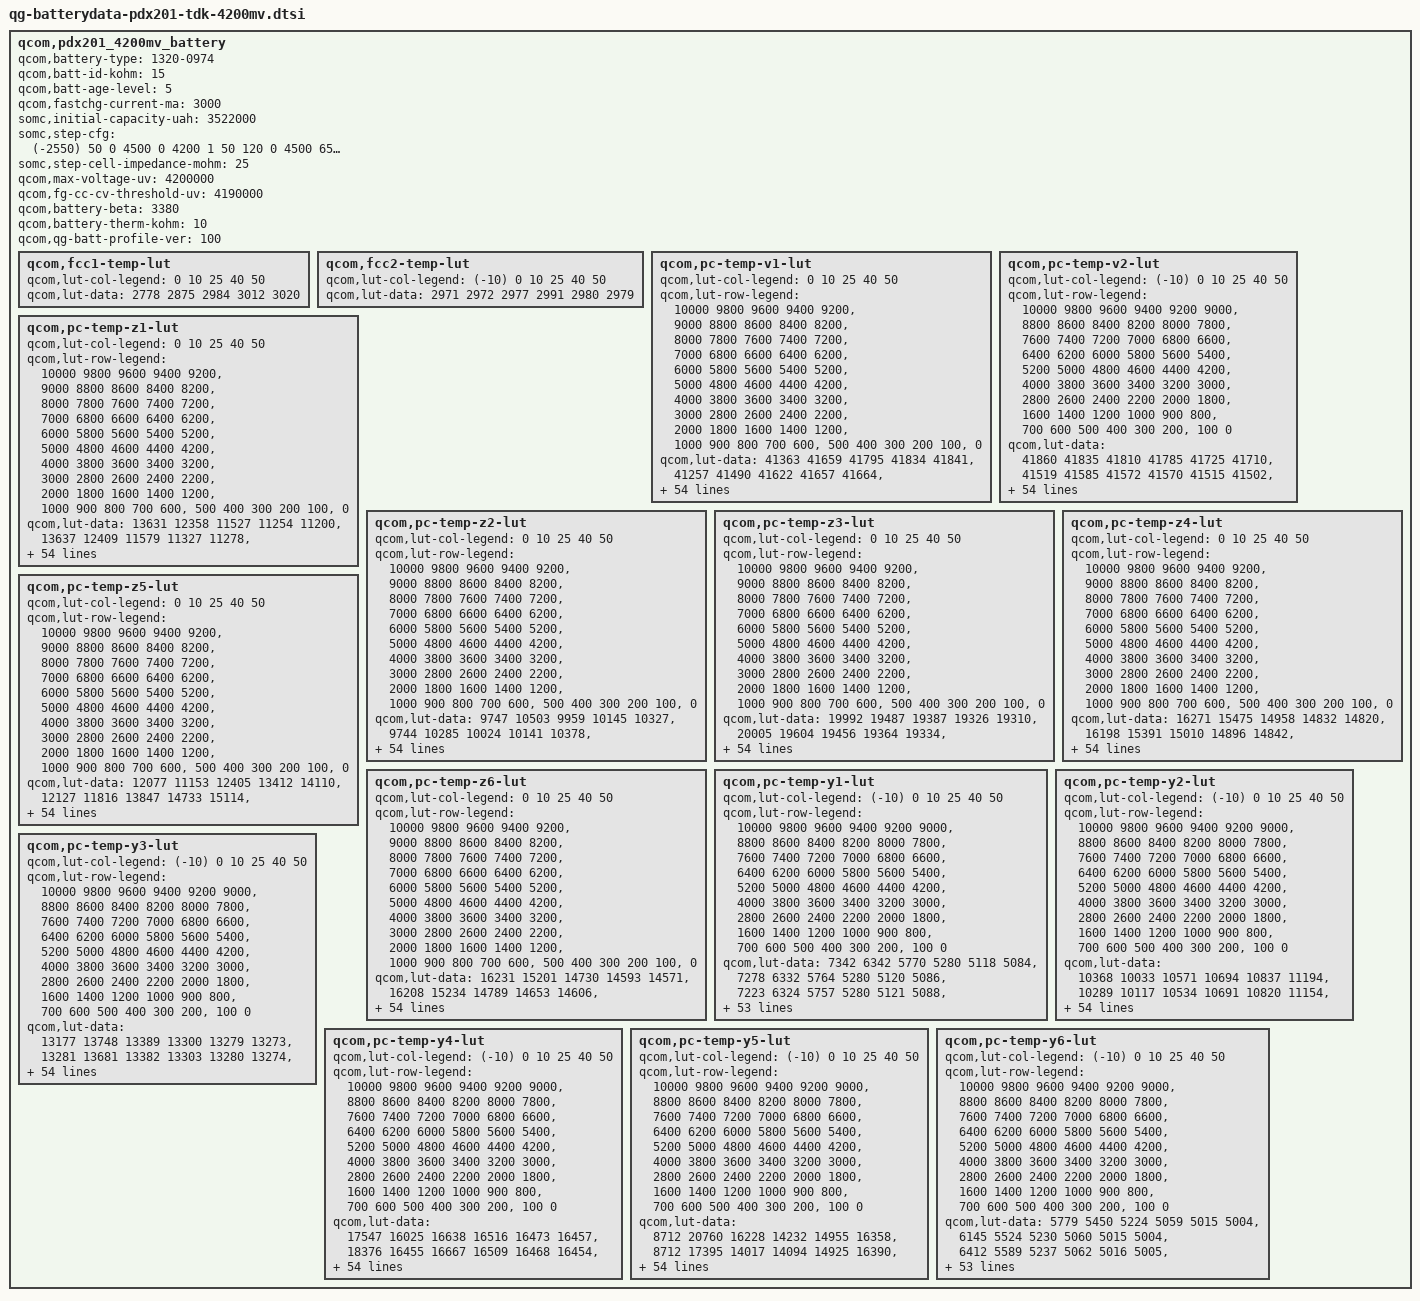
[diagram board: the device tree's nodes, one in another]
// SPDX-License-Identifier: GPL-2.0-only
/*
 * Copyright (c) 2019, The Linux Foundation. All rights reserved.
 */

qcom,pdx201_4200mv_battery {
	/* Added or Modified by SOMC */
	qcom,battery-type = "1320-0974";
	qcom,batt-id-kohm = <15>;
	qcom,batt-age-level = <5>;
	qcom,fastchg-current-ma = <3000>;
	somc,initial-capacity-uah = <3522000>;
	somc,step-cfg = <
		(-2550) 50    0 4500    0 4200 1
		   50  120    0 4500  650 4200 2
		  120  200    0 4100 1700 4200 3
		  120  200 4100 4500 1200 4200 3
		  200  450    0 4150 2400 4200 3
		  200  450 4150 4500 1700 4200 3
		  450  550    0 4500 1000 4200 4
		  550 2550    0 4500    0 4200 5
	>;
	somc,step-cell-impedance-mohm = <25>;

	/* Prepared by Qualcomm */
	/* 4176720_SoMC_Amuro2_2958mAh_averaged_MasterSlave_Sept16th2019 */
	qcom,max-voltage-uv = <4200000>;
	qcom,fg-cc-cv-threshold-uv = <4190000>;
	/* qcom,fastchg-current-ma = <1500>; */
	/* qcom,batt-id-kohm = <330>; */
	qcom,battery-beta = <3380>;
	qcom,battery-therm-kohm = <10>;
	/* qcom,battery-type = "4176720_SoMC_Amuro2_2958mAh_averaged_MasterSlave_Sept16th2019"; */
	qcom,qg-batt-profile-ver = <100>;

	qcom,fcc1-temp-lut {
		qcom,lut-col-legend = <0 10 25 40 50>;
		qcom,lut-data = <2778 2875 2984 3012 3020>;
	};

	qcom,fcc2-temp-lut {
		qcom,lut-col-legend = <(-10) 0 10 25 40 50>;
		qcom,lut-data = <2971 2972 2977 2991 2980 2979>;
	};

	qcom,pc-temp-v1-lut {
		qcom,lut-col-legend = <0 10 25 40 50>;
		qcom,lut-row-legend = <10000 9800 9600 9400 9200>,
			<9000 8800 8600 8400 8200>,
			<8000 7800 7600 7400 7200>,
			<7000 6800 6600 6400 6200>,
			<6000 5800 5600 5400 5200>,
			<5000 4800 4600 4400 4200>,
			<4000 3800 3600 3400 3200>,
			<3000 2800 2600 2400 2200>,
			<2000 1800 1600 1400 1200>,
			<1000 900 800 700 600>,
			<500 400 300 200 100>,
			<0>;
		qcom,lut-data = <41363 41659 41795 41834 41841>,
			<41257 41490 41622 41657 41664>,
			<41117 41335 41439 41473 41481>,
			<40935 41186 41267 41291 41298>,
			<40706 41032 41122 41115 41118>,
			<40473 40872 40979 40945 40941>,
			<40225 40695 40803 40775 40767>,
			<40003 40460 40584 40597 40595>,
			<39868 40171 40370 40420 40429>,
			<39778 39968 40165 40255 40270>,
			<39698 39863 39986 40098 40116>,
			<39618 39783 39868 39953 39968>,
			<39540 39694 39785 39821 39829>,
			<39454 39605 39693 39694 39694>,
			<39354 39509 39573 39570 39565>,
			<39251 39399 39438 39447 39441>,
			<39152 39278 39293 39300 39298>,
			<39056 39151 39136 39105 39112>,
			<38963 39014 38975 38922 38929>,
			<38874 38875 38786 38781 38789>,
			<38787 38731 38619 38660 38669>,
			<38699 38585 38528 38562 38567>,
			<38606 38481 38469 38481 38479>,
			<38520 38409 38413 38407 38398>,
			<38452 38354 38358 38335 38320>,
			<38394 38313 38306 38266 38246>,
			<38348 38281 38255 38205 38181>,
			<38312 38253 38207 38147 38122>,
			<38283 38225 38163 38096 38068>,
			<38258 38199 38123 38053 38021>,
			<38237 38173 38086 38015 37977>,
			<38218 38148 38056 37980 37938>,
			<38200 38124 38029 37948 37902>,
			<38182 38101 37999 37913 37863>,
			<38161 38078 37972 37877 37815>,
			<38127 38042 37936 37835 37761>,
			<38083 37989 37884 37781 37703>,
			<38025 37923 37812 37714 37639>,
			<37941 37847 37735 37637 37565>,
			<37841 37756 37650 37549 37478>,
			<37733 37651 37552 37448 37377>,
			<37612 37524 37429 37326 37255>,
			<37493 37397 37296 37193 37121>,
			<37381 37277 37175 37074 37003>,
			<37304 37207 37094 36993 36927>,
			<37258 37165 37052 36956 36890>,
			<37240 37151 37040 36943 36876>,
			<37216 37132 37025 36926 36859>,
			<37138 37075 36977 36871 36789>,
			<36915 36864 36774 36654 36551>,
			<36551 36506 36431 36311 36201>,
			<36108 36066 35997 35878 35764>,
			<35548 35511 35444 35327 35208>,
			<34814 34768 34704 34590 34461>,
			<33643 33611 33585 33479 33331>,
			<30000 30000 30000 30000 30000>;
	};

	qcom,pc-temp-v2-lut {
		qcom,lut-col-legend = <(-10) 0 10 25 40 50>;
		qcom,lut-row-legend = <10000 9800 9600 9400 9200 9000>,
			<8800 8600 8400 8200 8000 7800>,
			<7600 7400 7200 7000 6800 6600>,
			<6400 6200 6000 5800 5600 5400>,
			<5200 5000 4800 4600 4400 4200>,
			<4000 3800 3600 3400 3200 3000>,
			<2800 2600 2400 2200 2000 1800>,
			<1600 1400 1200 1000 900 800>,
			<700 600 500 400 300 200>,
			<100 0>;
		qcom,lut-data = <41860 41835 41810 41785 41725 41710>,
			<41519 41585 41572 41570 41515 41502>,
			<41273 41364 41357 41366 41315 41305>,
			<41172 41179 41171 41174 41124 41116>,
			<41134 41028 41014 40992 40943 40937>,
			<41075 40863 40853 40822 40771 40763>,
			<40784 40651 40681 40675 40611 40595>,
			<40344 40416 40497 40528 40457 40431>,
			<40042 40178 40276 40328 40287 40270>,
			<39806 39923 40003 40063 40102 40113>,
			<39624 39730 39797 39870 39937 39962>,
			<39503 39622 39691 39774 39809 39822>,
			<39398 39534 39605 39693 39691 39688>,
			<39258 39416 39485 39585 39567 39554>,
			<39084 39272 39334 39454 39439 39425>,
			<38877 39119 39175 39304 39295 39282>,
			<38567 38957 39006 39116 39110 39100>,
			<38268 38795 38841 38924 38917 38911>,
			<38163 38660 38706 38768 38760 38756>,
			<38116 38547 38592 38631 38621 38621>,
			<38076 38424 38488 38516 38506 38506>,
			<38036 38257 38394 38421 38412 38411>,
			<37999 38100 38308 38336 38329 38327>,
			<37962 38014 38231 38257 38250 38247>,
			<37924 37958 38162 38185 38177 38175>,
			<37888 37917 38092 38119 38111 38107>,
			<37855 37888 38015 38059 38051 38046>,
			<37824 37862 37944 38002 37996 37989>,
			<37791 37832 37891 37950 37945 37935>,
			<37757 37800 37850 37902 37897 37886>,
			<37723 37769 37813 37855 37849 37836>,
			<37692 37743 37781 37809 37801 37789>,
			<37659 37716 37749 37761 37748 37734>,
			<37620 37683 37715 37709 37679 37652>,
			<37575 37644 37678 37656 37595 37544>,
			<37526 37601 37637 37599 37517 37452>,
			<37473 37553 37588 37536 37449 37381>,
			<37414 37498 37532 37470 37383 37315>,
			<37346 37432 37465 37405 37318 37249>,
			<37270 37353 37387 37336 37252 37185>,
			<37198 37266 37301 37255 37174 37108>,
			<37132 37162 37204 37155 37077 37008>,
			<37069 37057 37094 37034 36966 36900>,
			<37007 36957 36967 36914 36849 36790>,
			<36933 36891 36906 36877 36821 36763>,
			<36862 36836 36874 36852 36794 36736>,
			<36807 36805 36854 36830 36771 36715>,
			<36735 36761 36824 36799 36734 36677>,
			<36635 36671 36749 36703 36631 36559>,
			<36439 36490 36547 36447 36370 36274>,
			<36127 36161 36179 36064 35986 35882>,
			<35695 35700 35709 35585 35505 35399>,
			<35117 35109 35124 34984 34898 34778>,
			<34298 34325 34351 34169 34071 33930>,
			<33099 33187 33260 32937 32865 32691>,
			<29585 29616 29564 29645 29742 29541>;
	};

	qcom,pc-temp-z1-lut {
		qcom,lut-col-legend = <0 10 25 40 50>;
		qcom,lut-row-legend = <10000 9800 9600 9400 9200>,
			<9000 8800 8600 8400 8200>,
			<8000 7800 7600 7400 7200>,
			<7000 6800 6600 6400 6200>,
			<6000 5800 5600 5400 5200>,
			<5000 4800 4600 4400 4200>,
			<4000 3800 3600 3400 3200>,
			<3000 2800 2600 2400 2200>,
			<2000 1800 1600 1400 1200>,
			<1000 900 800 700 600>,
			<500 400 300 200 100>,
			<0>;
		qcom,lut-data = <13631 12358 11527 11254 11200>,
			<13637 12409 11579 11327 11278>,
			<13645 12445 11618 11357 11303>,
			<13655 12473 11646 11377 11323>,
			<13669 12480 11660 11390 11336>,
			<13676 12475 11668 11399 11345>,
			<13678 12467 11667 11403 11350>,
			<13678 12461 11662 11402 11354>,
			<13677 12455 11658 11401 11356>,
			<13669 12453 11658 11402 11358>,
			<13664 12456 11659 11405 11359>,
			<13670 12463 11662 11409 11360>,
			<13678 12470 11672 11411 11361>,
			<13683 12479 11680 11413 11363>,
			<13694 12487 11683 11415 11363>,
			<13707 12494 11686 11416 11364>,
			<13710 12502 11689 11417 11364>,
			<13710 12508 11693 11418 11365>,
			<13708 12512 11696 11419 11365>,
			<13705 12516 11699 11420 11366>,
			<13699 12521 11701 11422 11369>,
			<13696 12526 11704 11424 11370>,
			<13694 12530 11708 11427 11371>,
			<13693 12535 11712 11429 11372>,
			<13692 12540 11716 11432 11375>,
			<13690 12544 11719 11434 11378>,
			<13688 12551 11722 11437 11380>,
			<13689 12555 11725 11439 11381>,
			<13690 12552 11728 11442 11382>,
			<13691 12549 11732 11443 11384>,
			<13693 12549 11736 11445 11385>,
			<13696 12554 11738 11446 11386>,
			<13699 12559 11741 11447 11387>,
			<13702 12563 11744 11448 11388>,
			<13705 12568 11749 11449 11388>,
			<13711 12574 11753 11450 11389>,
			<13720 12583 11754 11451 11389>,
			<13721 12590 11754 11452 11390>,
			<13704 12590 11755 11453 11391>,
			<13683 12588 11758 11454 11392>,
			<13671 12589 11761 11455 11392>,
			<13664 12599 11761 11455 11393>,
			<13655 12603 11762 11455 11393>,
			<13645 12596 11764 11456 11393>,
			<13621 12588 11770 11457 11394>,
			<13621 12608 11769 11458 11394>,
			<13617 12584 11771 11457 11395>,
			<13639 12590 11770 11458 11394>,
			<13640 12590 11772 11459 11394>,
			<13624 12603 11778 11460 11395>,
			<13638 12609 11787 11464 11397>,
			<13669 12634 11797 11471 11403>,
			<13728 12685 11818 11479 11410>,
			<13708 12704 11843 11494 11421>,
			<13708 12704 11843 11494 11421>,
			<13708 12704 11843 11494 11421>;
	};

	qcom,pc-temp-z2-lut {
		qcom,lut-col-legend = <0 10 25 40 50>;
		qcom,lut-row-legend = <10000 9800 9600 9400 9200>,
			<9000 8800 8600 8400 8200>,
			<8000 7800 7600 7400 7200>,
			<7000 6800 6600 6400 6200>,
			<6000 5800 5600 5400 5200>,
			<5000 4800 4600 4400 4200>,
			<4000 3800 3600 3400 3200>,
			<3000 2800 2600 2400 2200>,
			<2000 1800 1600 1400 1200>,
			<1000 900 800 700 600>,
			<500 400 300 200 100>,
			<0>;
		qcom,lut-data = <9747 10503 9959 10145 10327>,
			<9744 10285 10024 10141 10378>,
			<9740 10161 10225 10449 10729>,
			<9732 10069 10320 10778 11102>,
			<9720 10028 10290 10791 11124>,
			<9715 10028 10249 10776 11027>,
			<9719 10030 10234 10753 10979>,
			<9725 9981 10232 10703 10990>,
			<9732 9866 10222 10633 11001>,
			<9741 9810 10145 10478 10873>,
			<9748 9822 10068 10232 10497>,
			<9754 9844 10057 10163 10349>,
			<9758 9863 10049 10195 10364>,
			<9762 9880 10047 10228 10385>,
			<9765 9900 10081 10228 10393>,
			<9769 9925 10132 10219 10395>,
			<9774 9951 10158 10231 10405>,
			<9781 9970 10177 10371 10439>,
			<9789 9984 10182 10489 10470>,
			<9795 9996 10167 10405 10467>,
			<9801 10013 10150 10236 10442>,
			<9807 10031 10147 10199 10437>,
			<9817 10036 10150 10241 10472>,
			<9825 10022 10156 10294 10502>,
			<9828 10005 10179 10362 10462>,
			<9829 9999 10206 10433 10376>,
			<9830 9996 10219 10433 10324>,
			<9828 9996 10230 10371 10288>,
			<9825 9998 10233 10334 10271>,
			<9825 10003 10216 10338 10279>,
			<9826 10008 10199 10345 10298>,
			<9828 10017 10200 10357 10322>,
			<9829 10023 10206 10375 10361>,
			<9831 10025 10215 10396 10404>,
			<9833 10027 10236 10426 10459>,
			<9835 10030 10257 10454 10510>,
			<9838 10035 10267 10469 10534>,
			<9842 10042 10276 10483 10550>,
			<9853 10048 10280 10498 10564>,
			<9869 10055 10285 10518 10582>,
			<9885 10059 10292 10532 10594>,
			<9903 10061 10300 10520 10589>,
			<9927 10066 10307 10498 10580>,
			<9965 10090 10302 10493 10574>,
			<10203 10207 10347 10498 10594>,
			<10210 10266 10390 10528 10626>,
			<10206 10256 10365 10525 10624>,
			<10206 10252 10333 10527 10681>,
			<10232 10283 10380 10643 10777>,
			<10252 10309 10465 10626 10537>,
			<10212 10262 10419 10527 10444>,
			<10108 10237 10374 10467 10371>,
			<10017 10179 10315 10386 10322>,
			<9654 10025 10258 10319 10251>,
			<9654 10025 10258 10319 10251>,
			<9654 10025 10258 10319 10251>;
	};

	qcom,pc-temp-z3-lut {
		qcom,lut-col-legend = <0 10 25 40 50>;
		qcom,lut-row-legend = <10000 9800 9600 9400 9200>,
			<9000 8800 8600 8400 8200>,
			<8000 7800 7600 7400 7200>,
			<7000 6800 6600 6400 6200>,
			<6000 5800 5600 5400 5200>,
			<5000 4800 4600 4400 4200>,
			<4000 3800 3600 3400 3200>,
			<3000 2800 2600 2400 2200>,
			<2000 1800 1600 1400 1200>,
			<1000 900 800 700 600>,
			<500 400 300 200 100>,
			<0>;
		qcom,lut-data = <19992 19487 19387 19326 19310>,
			<20005 19604 19456 19364 19334>,
			<20018 19695 19493 19381 19353>,
			<20040 19771 19511 19392 19363>,
			<20081 19802 19517 19406 19369>,
			<20112 19806 19521 19420 19374>,
			<20134 19802 19524 19425 19375>,
			<20148 19792 19525 19416 19373>,
			<20142 19778 19524 19403 19369>,
			<20101 19759 19508 19390 19361>,
			<20061 19726 19484 19374 19343>,
			<20037 19692 19459 19367 19335>,
			<20018 19677 19427 19365 19331>,
			<20012 19668 19413 19365 19327>,
			<20012 19664 19429 19365 19326>,
			<20013 19666 19456 19364 19327>,
			<20016 19670 19479 19367 19330>,
			<20021 19678 19502 19385 19341>,
			<20025 19702 19512 19400 19351>,
			<20027 19728 19514 19390 19344>,
			<20030 19748 19514 19371 19325>,
			<20034 19767 19507 19363 19320>,
			<20049 19772 19491 19358 19328>,
			<20063 19755 19479 19356 19338>,
			<20064 19733 19471 19371 19353>,
			<20058 19719 19466 19396 19372>,
			<20050 19708 19474 19408 19376>,
			<20041 19700 19495 19415 19373>,
			<20030 19694 19507 19419 19369>,
			<20019 19690 19513 19415 19366>,
			<20009 19690 19516 19407 19362>,
			<19999 19691 19513 19401 19358>,
			<19988 19692 19504 19395 19352>,
			<19977 19690 19498 19391 19350>,
			<19968 19688 19493 19387 19351>,
			<19963 19687 19491 19384 19353>,
			<19959 19687 19490 19381 19352>,
			<19952 19686 19490 19378 19350>,
			<19936 19682 19489 19376 19348>,
			<19917 19670 19483 19376 19345>,
			<19902 19662 19477 19376 19342>,
			<19888 19659 19474 19375 19342>,
			<19862 19653 19472 19372 19342>,
			<19811 19637 19465 19370 19343>,
			<19669 19563 19444 19364 19338>,
			<19645 19535 19423 19343 19327>,
			<19634 19528 19413 19341 19325>,
			<19619 19521 19408 19339 19319>,
			<19613 19514 19402 19329 19317>,
			<19606 19508 19391 19334 19338>,
			<19602 19515 19396 19339 19346>,
			<19598 19507 19390 19345 19346>,
			<19564 19472 19391 19349 19345>,
			<19422 19411 19381 19357 19356>,
			<19422 19411 19381 19357 19356>,
			<19422 19411 19381 19357 19356>;
	};

	qcom,pc-temp-z4-lut {
		qcom,lut-col-legend = <0 10 25 40 50>;
		qcom,lut-row-legend = <10000 9800 9600 9400 9200>,
			<9000 8800 8600 8400 8200>,
			<8000 7800 7600 7400 7200>,
			<7000 6800 6600 6400 6200>,
			<6000 5800 5600 5400 5200>,
			<5000 4800 4600 4400 4200>,
			<4000 3800 3600 3400 3200>,
			<3000 2800 2600 2400 2200>,
			<2000 1800 1600 1400 1200>,
			<1000 900 800 700 600>,
			<500 400 300 200 100>,
			<0>;
		qcom,lut-data = <16271 15475 14958 14832 14820>,
			<16198 15391 15010 14896 14842>,
			<16107 15298 14957 14874 14831>,
			<15989 15197 14909 14834 14795>,
			<15850 15111 14881 14806 14770>,
			<15733 15023 14857 14783 14750>,
			<15637 14965 14829 14762 14731>,
			<15554 14968 14798 14741 14713>,
			<15484 14986 14782 14726 14700>,
			<15424 14995 14782 14724 14698>,
			<15371 14977 14787 14729 14707>,
			<15320 14947 14790 14724 14707>,
			<15273 14921 14794 14713 14700>,
			<15236 14894 14794 14703 14693>,
			<15208 14875 14769 14696 14687>,
			<15185 14868 14738 14690 14680>,
			<15166 14863 14737 14693 14680>,
			<15150 14863 14748 14735 14722>,
			<15138 14868 14764 14787 14778>,
			<15129 14878 14836 14833 14819>,
			<15121 14908 14911 14874 14856>,
			<15119 14959 14917 14882 14863>,
			<15124 14980 14913 14876 14845>,
			<15131 14984 14907 14866 14820>,
			<15136 14985 14900 14837 14791>,
			<15140 14983 14890 14795 14755>,
			<15142 14975 14869 14766 14734>,
			<15140 14966 14833 14744 14722>,
			<15133 14956 14807 14729 14712>,
			<15125 14944 14787 14719 14702>,
			<15114 14932 14775 14712 14694>,
			<15101 14920 14772 14710 14691>,
			<15089 14910 14771 14709 14690>,
			<15077 14903 14771 14709 14690>,
			<15066 14898 14772 14715 14701>,
			<15056 14899 14775 14725 14716>,
			<15047 14909 14786 14738 14723>,
			<15040 14919 14807 14754 14728>,
			<15035 14923 14813 14759 14729>,
			<15029 14925 14811 14754 14727>,
			<15021 14926 14810 14748 14725>,
			<15010 14921 14813 14754 14728>,
			<14991 14912 14816 14763 14735>,
			<14952 14881 14806 14760 14733>,
			<14849 14808 14766 14740 14720>,
			<14831 14774 14724 14705 14681>,
			<14829 14772 14720 14689 14662>,
			<14824 14766 14713 14676 14654>,
			<14818 14764 14719 14693 14672>,
			<14827 14782 14754 14715 14668>,
			<14854 14785 14753 14714 14663>,
			<14874 14793 14760 14707 14663>,
			<14913 14827 14757 14701 14663>,
			<15071 14884 14763 14690 14652>,
			<15071 14884 14763 14690 14652>,
			<15071 14884 14763 14690 14652>;
	};

	qcom,pc-temp-z5-lut {
		qcom,lut-col-legend = <0 10 25 40 50>;
		qcom,lut-row-legend = <10000 9800 9600 9400 9200>,
			<9000 8800 8600 8400 8200>,
			<8000 7800 7600 7400 7200>,
			<7000 6800 6600 6400 6200>,
			<6000 5800 5600 5400 5200>,
			<5000 4800 4600 4400 4200>,
			<4000 3800 3600 3400 3200>,
			<3000 2800 2600 2400 2200>,
			<2000 1800 1600 1400 1200>,
			<1000 900 800 700 600>,
			<500 400 300 200 100>,
			<0>;
		qcom,lut-data = <12077 11153 12405 13412 14110>,
			<12127 11816 13847 14733 15114>,
			<12206 12470 14746 15327 15991>,
			<12365 13130 15343 15775 16527>,
			<12685 13849 15686 16659 17195>,
			<13055 14786 16036 18032 17986>,
			<13566 15506 16749 19075 18936>,
			<14002 15728 17857 19684 20495>,
			<14094 15871 18318 19868 21803>,
			<14110 15918 17716 18982 20944>,
			<14131 15636 16826 17193 18036>,
			<14222 15272 16008 16903 16968>,
			<14429 15314 14769 17499 17057>,
			<14724 15897 14230 18253 17221>,
			<15316 16682 15491 18940 17671>,
			<16080 17494 18034 19760 18760>,
			<16781 18571 22683 21584 20311>,
			<17469 20371 30354 28521 23670>,
			<18173 24019 33594 34051 26544>,
			<18902 27683 32166 30052 24169>,
			<19718 30714 29823 21354 17825>,
			<20762 33773 27121 17425 15298>,
			<22615 34532 22497 15722 14843>,
			<24204 30492 19379 15008 14677>,
			<24440 25519 17675 15574 15551>,
			<24436 23377 16719 16765 17355>,
			<24386 21998 17133 18087 18446>,
			<24009 21272 18528 20026 19032>,
			<23288 20897 19964 21799 19724>,
			<22728 20674 21972 23150 21085>,
			<22318 20767 23554 24229 22654>,
			<21987 21368 23840 24895 23611>,
			<21746 21976 23965 25395 24331>,
			<21540 22380 24013 25545 24589>,
			<21444 22720 23943 24803 24354>,
			<21617 22940 23790 23503 23865>,
			<22035 23110 23443 21916 22867>,
			<22490 23198 22761 19900 20867>,
			<23105 22744 21953 18964 19400>,
			<23653 21742 20828 18753 18589>,
			<23883 21395 19881 18552 17924>,
			<24039 21591 19365 17842 17155>,
			<24006 21932 19057 16951 16558>,
			<23803 22619 19040 16755 16572>,
			<25192 22969 19788 17104 16578>,
			<23928 23391 20848 17001 17490>,
			<22753 22355 19671 17451 19089>,
			<21692 21934 19647 18490 19663>,
			<21977 21874 18990 16408 16883>,
			<21629 20131 16096 14707 17476>,
			<18906 19212 15947 14587 18221>,
			<16918 17648 15090 14948 18241>,
			<14918 14806 14897 15124 17793>,
			<11720 12672 14080 15915 20571>,
			<11720 12672 14080 15915 20571>,
			<11720 12672 14080 15915 20571>;
	};

	qcom,pc-temp-z6-lut {
		qcom,lut-col-legend = <0 10 25 40 50>;
		qcom,lut-row-legend = <10000 9800 9600 9400 9200>,
			<9000 8800 8600 8400 8200>,
			<8000 7800 7600 7400 7200>,
			<7000 6800 6600 6400 6200>,
			<6000 5800 5600 5400 5200>,
			<5000 4800 4600 4400 4200>,
			<4000 3800 3600 3400 3200>,
			<3000 2800 2600 2400 2200>,
			<2000 1800 1600 1400 1200>,
			<1000 900 800 700 600>,
			<500 400 300 200 100>,
			<0>;
		qcom,lut-data = <16231 15201 14730 14593 14571>,
			<16208 15234 14789 14653 14606>,
			<16180 15236 14795 14654 14612>,
			<16145 15232 14796 14652 14610>,
			<16103 15222 14792 14651 14608>,
			<16068 15189 14783 14649 14602>,
			<16037 15157 14773 14646 14596>,
			<16005 15148 14761 14633 14588>,
			<15967 15144 14749 14617 14580>,
			<15923 15137 14739 14608 14573>,
			<15885 15114 14730 14601 14567>,
			<15855 15083 14718 14595 14561>,
			<15830 15065 14703 14589 14556>,
			<15814 15050 14697 14584 14551>,
			<15803 15043 14697 14581 14548>,
			<15795 15043 14698 14579 14546>,
			<15791 15043 14703 14581 14547>,
			<15788 15046 14720 14610 14572>,
			<15786 15061 14739 14640 14601>,
			<15784 15081 14772 14652 14613>,
			<15783 15108 14802 14660 14620>,
			<15783 15141 14802 14661 14621>,
			<15794 15151 14793 14657 14618>,
			<15806 15145 14784 14652 14614>,
			<15808 15136 14778 14647 14609>,
			<15806 15129 14772 14643 14604>,
			<15804 15121 14767 14638 14598>,
			<15799 15114 14763 14633 14591>,
			<15791 15106 14759 14627 14584>,
			<15782 15100 14755 14621 14578>,
			<15772 15095 14751 14615 14573>,
			<15762 15092 14746 14610 14568>,
			<15753 15089 14742 14605 14564>,
			<15744 15087 14740 14603 14563>,
			<15736 15084 14739 14605 14568>,
			<15729 15085 14739 14607 14575>,
			<15724 15091 14743 14610 14577>,
			<15716 15096 14753 14615 14578>,
			<15704 15095 14755 14617 14579>,
			<15690 15092 14751 14614 14576>,
			<15678 15089 14747 14612 14573>,
			<15664 15086 14748 14614 14575>,
			<15641 15081 14748 14616 14578>,
			<15598 15061 14741 14614 14577>,
			<15484 14993 14713 14602 14570>,
			<15463 14965 14684 14576 14546>,
			<15455 14960 14677 14568 14537>,
			<15449 14955 14671 14561 14530>,
			<15448 14954 14671 14564 14535>,
			<15454 14961 14681 14576 14547>,
			<15474 14971 14686 14579 14549>,
			<15494 14979 14688 14581 14551>,
			<15516 14988 14692 14582 14553>,
			<15544 15000 14696 14585 14556>,
			<15544 15000 14696 14585 14556>,
			<15544 15000 14696 14585 14556>;
	};

	qcom,pc-temp-y1-lut {
		qcom,lut-col-legend = <(-10) 0 10 25 40 50>;
		qcom,lut-row-legend = <10000 9800 9600 9400 9200 9000>,
			<8800 8600 8400 8200 8000 7800>,
			<7600 7400 7200 7000 6800 6600>,
			<6400 6200 6000 5800 5600 5400>,
			<5200 5000 4800 4600 4400 4200>,
			<4000 3800 3600 3400 3200 3000>,
			<2800 2600 2400 2200 2000 1800>,
			<1600 1400 1200 1000 900 800>,
			<700 600 500 400 300 200>,
			<100 0>;
		qcom,lut-data = <7342 6342 5770 5280 5118 5084>,
			<7278 6332 5764 5280 5120 5086>,
			<7223 6324 5757 5280 5121 5088>,
			<7181 6319 5750 5281 5121 5089>,
			<7154 6316 5744 5281 5121 5090>,
			<7145 6315 5741 5281 5122 5091>,
			<7159 6317 5739 5280 5121 5091>,
			<7182 6321 5737 5280 5120 5091>,
			<7191 6326 5738 5281 5121 5091>,
			<7205 6337 5741 5284 5124 5092>,
			<7212 6344 5744 5287 5125 5092>,
			<7202 6341 5750 5288 5124 5092>,
			<7189 6336 5756 5290 5123 5092>,
			<7184 6336 5755 5290 5124 5093>,
			<7170 6337 5749 5289 5125 5094>,
			<7161 6340 5746 5289 5126 5095>,
			<7170 6355 5745 5291 5126 5095>,
			<7182 6373 5746 5295 5125 5095>,
			<7178 6373 5748 5298 5126 5095>,
			<7157 6361 5753 5301 5129 5095>,
			<7144 6356 5757 5304 5131 5095>,
			<7143 6363 5759 5305 5133 5098>,
			<7142 6372 5761 5306 5134 5100>,
			<7144 6374 5764 5308 5134 5100>,
			<7151 6374 5771 5311 5134 5099>,
			<7157 6375 5775 5314 5134 5099>,
			<7159 6379 5778 5318 5136 5100>,
			<7160 6385 5782 5321 5138 5103>,
			<7155 6385 5784 5325 5140 5105>,
			<7134 6378 5787 5328 5142 5107>,
			<7123 6373 5791 5331 5144 5107>,
			<7135 6370 5799 5334 5146 5108>,
			<7151 6368 5808 5337 5148 5108>,
			<7151 6367 5816 5339 5149 5109>,
			<7146 6366 5825 5341 5149 5110>,
			<7143 6365 5828 5344 5150 5110>,
			<7137 6364 5822 5349 5151 5112>,
			<7126 6363 5819 5353 5152 5113>,
			<7118 6362 5821 5353 5153 5113>,
			<7106 6362 5823 5354 5154 5113>,
			<7103 6362 5828 5355 5154 5112>,
			<7113 6360 5837 5358 5154 5111>,
			<7114 6358 5842 5361 5155 5111>,
			<7098 6359 5837 5365 5156 5112>,
			<7131 6369 5830 5366 5155 5113>,
			<7148 6375 5829 5363 5160 5111>,
			<7128 6371 5831 5365 5157 5112>,
			<7113 6370 5840 5365 5154 5113>,
			<7115 6381 5841 5367 5158 5112>,
			<7126 6379 5837 5373 5159 5113>,
			<7171 6391 5848 5378 5162 5116>,
			<7251 6424 5873 5387 5167 5118>,
			<7318 6425 5885 5402 5172 5124>,
			<7330 6478 5914 5423 5180 5130>,
			<7330 6478 5914 5423 5180 5130>,
			<7330 6478 5914 5423 5180 5130>;
	};

	qcom,pc-temp-y2-lut {
		qcom,lut-col-legend = <(-10) 0 10 25 40 50>;
		qcom,lut-row-legend = <10000 9800 9600 9400 9200 9000>,
			<8800 8600 8400 8200 8000 7800>,
			<7600 7400 7200 7000 6800 6600>,
			<6400 6200 6000 5800 5600 5400>,
			<5200 5000 4800 4600 4400 4200>,
			<4000 3800 3600 3400 3200 3000>,
			<2800 2600 2400 2200 2000 1800>,
			<1600 1400 1200 1000 900 800>,
			<700 600 500 400 300 200>,
			<100 0>;
		qcom,lut-data = <10368 10033 10571 10694 10837 11194>,
			<10289 10117 10534 10691 10820 11154>,
			<10257 10229 10500 10682 10804 11097>,
			<10261 10347 10470 10669 10792 11037>,
			<10289 10444 10450 10656 10784 10986>,
			<10332 10496 10443 10645 10783 10958>,
			<10426 10516 10448 10631 10789 10945>,
			<10538 10527 10459 10619 10798 10936>,
			<10581 10526 10483 10638 10803 10934>,
			<10603 10514 10542 10721 10798 10927>,
			<10611 10508 10578 10764 10794 10924>,
			<10562 10534 10583 10745 10794 10934>,
			<10452 10582 10586 10721 10799 10948>,
			<10271 10620 10599 10725 10833 10954>,
			<9931 10655 10634 10754 10920 10958>,
			<9729 10686 10668 10780 10975 10965>,
			<9692 10714 10691 10795 10979 11003>,
			<9672 10739 10714 10811 10975 11054>,
			<9664 10761 10743 10839 10981 11072>,
			<9659 10783 10777 10882 10998 11074>,
			<9657 10792 10806 10921 11004 11083>,
			<9655 10762 10827 10955 11006 11127>,
			<9654 10713 10848 10987 11013 11176>,
			<9653 10680 10878 11019 11040 11192>,
			<9653 10655 10916 11048 11100 11200>,
			<9653 10630 10930 11065 11131 11207>,
			<9653 10608 10909 11080 11167 11227>,
			<9653 10579 10880 11096 11213 11260>,
			<9653 10431 10868 11120 11268 11307>,
			<9653 10036 10861 11154 11358 11375>,
			<9653 9800 10848 11168 11394 11430>,
			<9653 9739 10790 11167 11375 11546>,
			<9653 9703 10715 11161 11355 11641>,
			<9653 9688 10660 11154 11356 11617>,
			<9653 9680 10612 11145 11359 11559>,
			<9653 9674 10577 11129 11365 11527>,
			<9653 9670 10554 11096 11385 11507>,
			<9653 9666 10534 11072 11407 11498>,
			<9653 9664 10507 11064 11411 11500>,
			<9653 9662 10478 11056 11397 11505>,
			<9653 9661 10451 11040 11393 11516>,
			<9652 9659 10429 11007 11415 11542>,
			<9652 9658 10407 10960 11396 11534>,
			<9652 9657 10385 10899 11231 11453>,
			<9652 9656 10346 10889 11249 11313>,
			<9652 9657 10383 10948 11244 11353>,
			<9652 9656 10376 10958 11212 11204>,
			<9652 9656 10367 10933 11247 11197>,
			<9652 9655 10359 10922 11164 11162>,
			<9652 9655 10346 10881 11161 11138>,
			<9652 9654 10293 10805 11055 11056>,
			<9651 9653 10260 10766 11003 10986>,
			<9650 9653 10226 10725 10934 10938>,
			<9649 9652 10197 10660 10890 10853>,
			<9649 9652 10197 10660 10890 10853>,
			<9649 9652 10197 10660 10890 10853>;
	};

	qcom,pc-temp-y3-lut {
		qcom,lut-col-legend = <(-10) 0 10 25 40 50>;
		qcom,lut-row-legend = <10000 9800 9600 9400 9200 9000>,
			<8800 8600 8400 8200 8000 7800>,
			<7600 7400 7200 7000 6800 6600>,
			<6400 6200 6000 5800 5600 5400>,
			<5200 5000 4800 4600 4400 4200>,
			<4000 3800 3600 3400 3200 3000>,
			<2800 2600 2400 2200 2000 1800>,
			<1600 1400 1200 1000 900 800>,
			<700 600 500 400 300 200>,
			<100 0>;
		qcom,lut-data = <13177 13748 13389 13300 13279 13273>,
			<13281 13681 13382 13303 13280 13274>,
			<13387 13605 13378 13305 13280 13275>,
			<13488 13534 13378 13306 13281 13276>,
			<13573 13481 13381 13306 13282 13276>,
			<13633 13461 13384 13306 13282 13277>,
			<13677 13474 13393 13305 13282 13277>,
			<13708 13494 13402 13303 13282 13278>,
			<13694 13497 13400 13303 13283 13278>,
			<13607 13495 13383 13303 13287 13278>,
			<13536 13492 13373 13304 13289 13278>,
			<13504 13485 13384 13309 13288 13280>,
			<13483 13475 13398 13316 13288 13283>,
			<13485 13468 13400 13319 13289 13283>,
			<13502 13462 13396 13322 13293 13283>,
			<13511 13454 13390 13322 13295 13282>,
			<13489 13443 13378 13317 13293 13280>,
			<13459 13428 13364 13310 13288 13277>,
			<13475 13413 13359 13307 13285 13276>,
			<13574 13395 13357 13305 13281 13275>,
			<13693 13386 13355 13303 13279 13275>,
			<13828 13384 13351 13302 13280 13275>,
			<13972 13383 13348 13300 13280 13275>,
			<14089 13380 13345 13300 13280 13275>,
			<14192 13375 13343 13299 13278 13275>,
			<14282 13372 13340 13299 13278 13276>,
			<14362 13384 13337 13301 13280 13277>,
			<14432 13397 13335 13303 13283 13277>,
			<14487 13396 13335 13302 13284 13277>,
			<14532 13389 13339 13302 13285 13277>,
			<14574 13386 13344 13301 13285 13277>,
			<14616 13402 13350 13301 13284 13278>,
			<14655 13424 13357 13301 13283 13279>,
			<14695 13435 13365 13300 13282 13277>,
			<14735 13443 13373 13300 13281 13273>,
			<14774 13453 13378 13301 13280 13272>,
			<14812 13467 13380 13301 13280 13272>,
			<14851 13486 13382 13302 13280 13272>,
			<14891 13513 13384 13303 13280 13273>,
			<14935 13556 13386 13303 13280 13274>,
			<14984 13605 13389 13304 13280 13274>,
			<15044 13663 13395 13305 13282 13273>,
			<15112 13730 13399 13306 13282 13272>,
			<15189 13809 13400 13307 13282 13273>,
			<15252 13904 13402 13308 13284 13275>,
			<15004 13789 13393 13307 13285 13276>,
			<15108 13856 13400 13308 13284 13281>,
			<15239 13921 13412 13316 13288 13287>,
			<15391 14000 13418 13316 13289 13285>,
			<15521 14093 13421 13313 13289 13281>,
			<15743 14192 13424 13321 13292 13283>,
			<16200 14378 13439 13326 13293 13287>,
			<16801 14664 13464 13335 13297 13289>,
			<17467 15068 13495 13342 13301 13290>,
			<17467 15068 13495 13342 13301 13290>,
			<17467 15068 13495 13342 13301 13290>;
	};

	qcom,pc-temp-y4-lut {
		qcom,lut-col-legend = <(-10) 0 10 25 40 50>;
		qcom,lut-row-legend = <10000 9800 9600 9400 9200 9000>,
			<8800 8600 8400 8200 8000 7800>,
			<7600 7400 7200 7000 6800 6600>,
			<6400 6200 6000 5800 5600 5400>,
			<5200 5000 4800 4600 4400 4200>,
			<4000 3800 3600 3400 3200 3000>,
			<2800 2600 2400 2200 2000 1800>,
			<1600 1400 1200 1000 900 800>,
			<700 600 500 400 300 200>,
			<100 0>;
		qcom,lut-data = <17547 16025 16638 16516 16473 16457>,
			<18376 16455 16667 16509 16468 16454>,
			<18878 16873 16695 16508 16467 16453>,
			<19135 17229 16721 16512 16469 16454>,
			<19228 17477 16744 16519 16473 16456>,
			<19240 17568 16763 16529 16477 16459>,
			<18794 17493 16781 16547 16485 16464>,
			<18137 17357 16794 16564 16494 16469>,
			<18031 17260 16795 16568 16500 16475>,
			<18073 17174 16787 16568 16503 16482>,
			<18117 17138 16783 16569 16508 16488>,
			<18158 17246 16829 16582 16516 16492>,
			<18190 17398 16893 16602 16525 16498>,
			<18162 17415 16898 16619 16538 16509>,
			<17985 17380 16878 16636 16556 16531>,
			<17757 17334 16852 16642 16563 16541>,
			<17407 17271 16806 16616 16547 16528>,
			<17078 17202 16757 16579 16521 16506>,
			<17036 17162 16736 16554 16503 16489>,
			<17046 17138 16722 16530 16486 16473>,
			<17056 17098 16718 16523 16480 16466>,
			<17062 16912 16719 16526 16480 16466>,
			<17068 16706 16722 16531 16481 16466>,
			<17076 16684 16727 16536 16485 16468>,
			<17089 16702 16735 16545 16493 16473>,
			<17099 16726 16737 16553 16502 16479>,
			<17107 16759 16700 16561 16509 16487>,
			<17115 16803 16655 16570 16518 16497>,
			<17124 16863 16645 16582 16528 16508>,
			<17135 16943 16641 16596 16542 16521>,
			<17149 16999 16640 16600 16551 16529>,
			<17175 17029 16664 16594 16559 16534>,
			<17197 17051 16699 16586 16563 16537>,
			<17198 17072 16723 16580 16549 16524>,
			<17194 17090 16745 16574 16513 16492>,
			<17190 17107 16763 16567 16499 16479>,
			<17181 17124 16776 16560 16498 16479>,
			<17171 17136 16788 16556 16498 16480>,
			<17162 17135 16800 16562 16501 16482>,
			<17153 17131 16812 16573 16508 16486>,
			<17150 17125 16825 16581 16512 16489>,
			<17165 17112 16842 16588 16514 16493>,
			<17193 17102 16847 16585 16512 16492>,
			<17246 17102 16840 16571 16497 16478>,
			<17312 17124 16856 16579 16508 16490>,
			<17264 17113 16802 16577 16516 16497>,
			<17281 17156 16833 16595 16526 16500>,
			<17312 17232 16873 16611 16531 16507>,
			<17331 17262 16910 16610 16530 16503>,
			<17322 17269 16902 16589 16504 16479>,
			<17331 17242 16888 16597 16504 16480>,
			<17506 17247 16917 16619 16516 16495>,
			<17818 17287 16972 16671 16546 16515>,
			<18427 17497 17064 16762 16612 16576>,
			<18427 17497 17064 16762 16612 16576>,
			<18427 17497 17064 16762 16612 16576>;
	};

	qcom,pc-temp-y5-lut {
		qcom,lut-col-legend = <(-10) 0 10 25 40 50>;
		qcom,lut-row-legend = <10000 9800 9600 9400 9200 9000>,
			<8800 8600 8400 8200 8000 7800>,
			<7600 7400 7200 7000 6800 6600>,
			<6400 6200 6000 5800 5600 5400>,
			<5200 5000 4800 4600 4400 4200>,
			<4000 3800 3600 3400 3200 3000>,
			<2800 2600 2400 2200 2000 1800>,
			<1600 1400 1200 1000 900 800>,
			<700 600 500 400 300 200>,
			<100 0>;
		qcom,lut-data = <8712 20760 16228 14232 14955 16358>,
			<8712 17395 14017 14094 14925 16390>,
			<9666 14613 12652 13897 14800 16300>,
			<10819 12512 11929 13649 14595 16110>,
			<11859 11186 11644 13358 14326 15842>,
			<12756 10737 11597 13034 14011 15518>,
			<13665 11559 12243 12563 13514 15090>,
			<14369 12775 13179 12141 13047 14603>,
			<14266 12966 13193 12066 13091 14144>,
			<13298 12868 12571 12051 13584 13656>,
			<12722 12784 12218 12050 13857 13445>,
			<13177 12734 12462 12272 13523 13749>,
			<14044 12697 12933 12656 13078 14153>,
			<14886 12781 13476 12992 13114 14075>,
			<15865 13196 14218 13333 13561 13562>,
			<16292 13575 14542 13626 14065 13305>,
			<14172 13768 14183 13928 14679 13658>,
			<11292 13944 13738 14177 15190 14260>,
			<10845 14210 13726 14304 15091 14862>,
			<10861 14600 13877 14389 14546 15598>,
			<10897 15089 13969 14342 14266 15900>,
			<10964 15940 13981 14001 14252 15744>,
			<11037 16708 13991 13686 14242 15478>,
			<11060 16162 14092 13629 14039 15226>,
			<11055 13846 14416 13554 13446 14942>,
			<11068 12639 14863 13560 13198 14792>,
			<11161 12660 15782 13931 13756 14862>,
			<11272 12703 16598 14442 14513 14961>,
			<11326 12440 16651 14827 14902 14876>,
			<11365 11700 16567 15209 15191 14703>,
			<11391 11358 16419 15685 15413 14685>,
			<11433 11432 15903 16418 15686 15387>,
			<11476 11520 15300 16874 15922 16058>,
			<11507 11516 14990 16652 16050 15841>,
			<11568 11468 14772 16223 16185 15248>,
			<11607 11453 14517 16045 16184 14971>,
			<11647 11492 14175 15883 15974 14836>,
			<11683 11523 13824 15705 15686 14715>,
			<11638 11523 13502 15384 15307 14629>,
			<11471 11546 13201 14938 14787 14514>,
			<11371 11568 13076 14591 14535 14291>,
			<11347 11580 13040 14272 14503 13613>,
			<11350 11539 12999 14263 14718 13559>,
			<11369 11375 12816 14532 15715 14498>,
			<11288 11351 12513 14307 15197 13984>,
			<11500 11292 12929 14286 14203 13427>,
			<11582 11341 12923 13870 13541 14338>,
			<11724 11360 13038 14339 13997 15922>,
			<12114 11509 13094 14315 14427 15638>,
			<12056 11708 13246 14519 15503 15454>,
			<11643 11667 13198 15628 16588 16224>,
			<10967 11487 13235 15965 16426 17925>,
			<10549 11389 13530 16719 17508 18179>,
			<10129 11180 14027 16712 17514 17613>,
			<10129 11180 14027 16712 17514 17613>,
			<10129 11180 14027 16712 17514 17613>;
	};

	qcom,pc-temp-y6-lut {
		qcom,lut-col-legend = <(-10) 0 10 25 40 50>;
		qcom,lut-row-legend = <10000 9800 9600 9400 9200 9000>,
			<8800 8600 8400 8200 8000 7800>,
			<7600 7400 7200 7000 6800 6600>,
			<6400 6200 6000 5800 5600 5400>,
			<5200 5000 4800 4600 4400 4200>,
			<4000 3800 3600 3400 3200 3000>,
			<2800 2600 2400 2200 2000 1800>,
			<1600 1400 1200 1000 900 800>,
			<700 600 500 400 300 200>,
			<100 0>;
		qcom,lut-data = <5779 5450 5224 5059 5015 5004>,
			<6145 5524 5230 5060 5015 5004>,
			<6412 5589 5237 5062 5016 5005>,
			<6590 5641 5245 5065 5017 5005>,
			<6689 5675 5252 5067 5019 5007>,
			<6718 5687 5260 5070 5020 5008>,
			<6630 5674 5271 5074 5023 5010>,
			<6492 5649 5281 5078 5025 5012>,
			<6443 5628 5279 5079 5028 5014>,
			<6421 5605 5265 5080 5032 5015>,
			<6413 5594 5258 5081 5035 5017>,
			<6432 5622 5279 5088 5036 5020>,
			<6458 5660 5307 5098 5038 5023>,
			<6457 5663 5309 5105 5043 5028>,
			<6429 5651 5300 5112 5051 5033>,
			<6389 5634 5288 5114 5055 5035>,
			<6308 5611 5267 5103 5048 5030>,
			<6225 5586 5244 5087 5037 5021>,
			<6244 5569 5235 5077 5029 5015>,
			<6388 5558 5231 5069 5021 5010>,
			<6540 5542 5229 5067 5018 5008>,
			<6668 5494 5228 5066 5018 5008>,
			<6789 5444 5227 5067 5019 5008>,
			<6883 5443 5228 5068 5020 5008>,
			<6962 5465 5230 5070 5021 5010>,
			<7029 5497 5230 5073 5023 5012>,
			<7088 5555 5219 5077 5027 5015>,
			<7139 5625 5206 5081 5031 5018>,
			<7179 5679 5206 5085 5036 5021>,
			<7211 5725 5211 5089 5041 5025>,
			<7244 5769 5218 5090 5043 5027>,
			<7279 5809 5235 5088 5044 5029>,
			<7312 5848 5256 5086 5045 5030>,
			<7342 5883 5275 5085 5041 5026>,
			<7370 5916 5294 5084 5029 5014>,
			<7396 5951 5311 5083 5025 5009>,
			<7420 5990 5323 5082 5024 5009>,
			<7444 6032 5335 5081 5024 5010>,
			<7471 6076 5348 5084 5025 5011>,
			<7502 6124 5362 5088 5028 5013>,
			<7539 6177 5378 5092 5029 5014>,
			<7586 6234 5400 5095 5031 5014>,
			<7645 6298 5419 5094 5030 5014>,
			<7716 6373 5435 5092 5026 5010>,
			<7782 6461 5454 5096 5032 5015>,
			<7593 6361 5394 5094 5034 5018>,
			<7675 6430 5416 5100 5036 5022>,
			<7783 6504 5445 5110 5041 5029>,
			<7902 6576 5469 5110 5041 5026>,
			<7997 6651 5485 5103 5034 5017>,
			<8178 6727 5504 5112 5036 5019>,
			<8628 6880 5560 5124 5041 5026>,
			<9236 7118 5636 5148 5053 5034>,
			<9977 7520 5727 5182 5076 5053>,
			<9977 7520 5727 5182 5076 5053>,
			<9977 7520 5727 5182 5076 5053>;
	};

};
